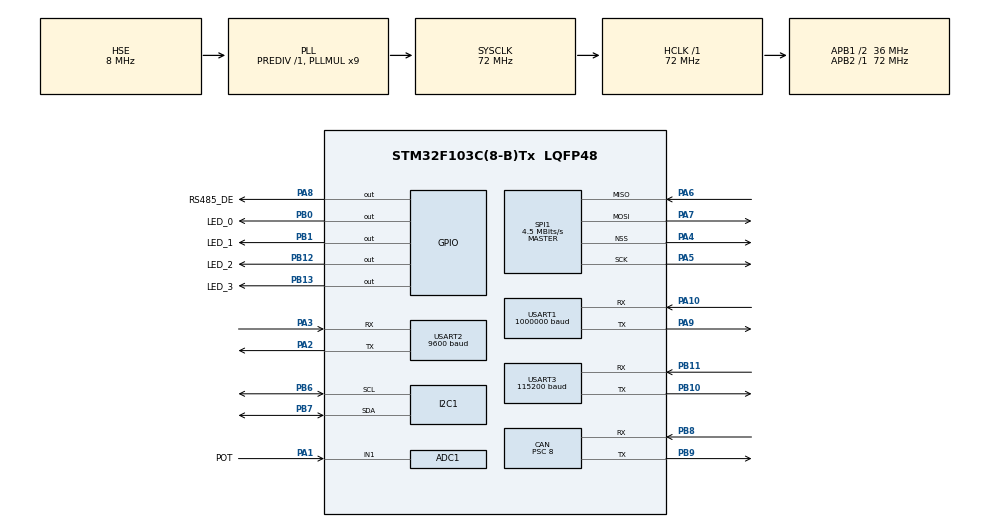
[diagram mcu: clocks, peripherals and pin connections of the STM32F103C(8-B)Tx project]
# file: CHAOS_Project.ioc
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ADC1.Channel-7\#ChannelInjectedConversion=ADC_CHANNEL_1
ADC1.Channel-8\#ChannelInjectedConversion=ADC_CHANNEL_1
ADC1.ContinuousConvMode=ENABLE
ADC1.EnableInjectedConversion=ENABLE
ADC1.EnableRegularConversion=DISABLE
ADC1.InjNumberOfConversion=2
ADC1.InjectedOffset-7\#ChannelInjectedConversion=0
ADC1.InjectedOffset-8\#ChannelInjectedConversion=0
ADC1.InjectedRank-7\#ChannelInjectedConversion=1
ADC1.InjectedRank-8\#ChannelInjectedConversion=2
ADC1.SamplingTime-7\#ChannelInjectedConversion=ADC_SAMPLETIME_1CYCLE_5
ADC1.SamplingTime-8\#ChannelInjectedConversion=ADC_SAMPLETIME_1CYCLE_5
ADC1.master=1
CAN.AWUM=ENABLE
CAN.BS1=CAN_BS1_3TQ
CAN.BS2=CAN_BS2_5TQ
CAN.CalculateBaudRate=500000
CAN.CalculateTimeBit=2000
CAN.CalculateTimeQuantum=222.22222222222223
CAN.NART=ENABLE
CAN.Prescaler=8
Mcu.Family=STM32F1
Mcu.Name=STM32F103C(8-B)Tx
Mcu.Package=LQFP48
NVIC.PriorityGroup=NVIC_PRIORITYGROUP_4
NVIC.TIM2_IRQn=true\:0\:0\:false\:false\:true\:true\:true\:true
NVIC.USB_LP_CAN1_RX0_IRQn=true\:0\:0\:false\:false\:true\:false\:true\:true
PA1.GPIO_Label=POT
PA1.Signal=ADCx_IN1
PA10.Mode=Asynchronous
PA10.Signal=USART1_RX
PA13.Mode=Serial_Wire
PA13.Signal=SYS_JTMS-SWDIO
PA14.Mode=Serial_Wire
PA14.Signal=SYS_JTCK-SWCLK
PA2.Mode=LIN
PA2.Signal=USART2_TX
PA3.Mode=LIN
PA3.Signal=USART2_RX
PA4.Mode=NSS_Signal_Hard_Output
PA4.Signal=SPI1_NSS
PA5.Mode=Full_Duplex_Master
PA5.Signal=SPI1_SCK
PA6.Mode=Full_Duplex_Master
PA6.Signal=SPI1_MISO
PA7.Mode=Full_Duplex_Master
PA7.Signal=SPI1_MOSI
PA8.GPIO_Label=RS485_DE
PA8.Signal=GPIO_Output
PA9.Mode=Asynchronous
PA9.Signal=USART1_TX
PB0.GPIO_Label=LED_0
PB0.Signal=GPIO_Output
PB1.GPIO_Label=LED_1
PB1.Signal=GPIO_Output
PB10.Mode=Asynchronous
PB10.Signal=USART3_TX
PB11.Mode=Asynchronous
PB11.Signal=USART3_RX
PB12.GPIO_Label=LED_2
PB12.Signal=GPIO_Output
PB13.GPIO_Label=LED_3
PB13.Signal=GPIO_Output
PB6.Mode=I2C
PB6.Signal=I2C1_SCL
PB7.Mode=I2C
PB7.Signal=I2C1_SDA
PB8.Mode=CAN_Activate
PB8.Signal=CAN_RX
PB9.Mode=CAN_Activate
PB9.Signal=CAN_TX
PD0-OSC_IN.Mode=HSE-External-Oscillator
PD0-OSC_IN.Signal=RCC_OSC_IN
PD1-OSC_OUT.Mode=HSE-External-Oscillator
PD1-OSC_OUT.Signal=RCC_OSC_OUT
ProjectManager.HeapSize=0x200
ProjectManager.StackSize=0x400
ProjectManager.TargetToolchain=STM32CubeIDE
RCC.ADCPresc=RCC_ADCPCLK2_DIV6
RCC.AHBFreq_Value=72000000
RCC.APB1CLKDivider=RCC_HCLK_DIV2
RCC.APB1Freq_Value=36000000
RCC.APB1TimFreq_Value=72000000
RCC.APB2Freq_Value=72000000
RCC.APB2TimFreq_Value=72000000
RCC.HCLKFreq_Value=72000000
RCC.PLLMUL=RCC_PLL_MUL9
RCC.PLLSourceVirtual=RCC_PLLSOURCE_HSE
RCC.RTCClockSelection=RCC_RTCCLKSOURCE_LSE
RCC.SYSCLKFreq_VALUE=72000000
RCC.SYSCLKSource=RCC_SYSCLKSOURCE_PLLCLK
RCC.USBFreq_Value=48000000
RCC.USBPrescaler=RCC_USBCLKSOURCE_PLL_DIV1_5
SH.ADCx_IN1.0=ADC1_IN1,IN1
SPI1.BaudRatePrescaler=SPI_BAUDRATEPRESCALER_16
SPI1.CalculateBaudRate=4.5 MBits/s
SPI1.Direction=SPI_DIRECTION_2LINES
SPI1.Mode=SPI_MODE_MASTER
SPI1.VirtualNSS=VM_NSSHARD
SPI1.VirtualType=VM_MASTER
TIM2.Period=9
TIM2.Prescaler=7200
USART1.BaudRate=1000000
USART1.VirtualMode=VM_ASYNC
USART2.BaudRate=9600
USART2.VirtualMode=VM_ASYNC
USART3.BaudRate=115200
USART3.VirtualMode=VM_ASYNC
VP_TIM2_VS_ClockSourceINT.Mode=Internal
board=custom

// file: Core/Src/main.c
/* USER CODE BEGIN Header */
/**
  ******************************************************************************
  * @file           : main.c
  * @brief          : Main program body
  ******************************************************************************
  * @attention
  *
  * Copyright (c) 2025 STMicroelectronics.
  * All rights reserved.
  *
  * This software is licensed under terms that can be found in the LICENSE file
  * in the root directory of this software component.
  * If no LICENSE file comes with this software, it is provided AS-IS.
  *
  ******************************************************************************
  */
/* USER CODE END Header */
#include "main.h"

/* USER CODE BEGIN Includes */
#include "os.h"
#include "strings.h"
#include "ssd1306.h"
#include <sys/unistd.h> // STDOUT_FILENO
#include <errno.h>
/* USER CODE END Includes */

/* USER CODE BEGIN PD */
#define UART_PRINTF
/* USER CODE END PD */

ADC_HandleTypeDef hadc1;

CAN_HandleTypeDef hcan;

I2C_HandleTypeDef hi2c1;

SPI_HandleTypeDef hspi1;

TIM_HandleTypeDef htim2;

UART_HandleTypeDef huart1;
UART_HandleTypeDef huart2;
UART_HandleTypeDef huart3;

/* USER CODE BEGIN PV */
ssd1306_t oled;
/* USER CODE END PV */

void SystemClock_Config(void);
static void MX_GPIO_Init(void);
static void MX_TIM2_Init(void);
static void MX_CAN_Init(void);
static void MX_USART1_UART_Init(void);
static void MX_USART3_UART_Init(void);
static void MX_ADC1_Init(void);
static void MX_I2C1_Init(void);
static void MX_SPI1_Init(void);
static void MX_USART2_UART_Init(void);

/* USER CODE BEGIN 0 */

/* OS tick timer interrupt */
void HAL_TIM_PeriodElapsedCallback(TIM_HandleTypeDef *htim)
{
  if(htim->Instance == TIM2)
  {
    /* OS tick service */
    Os_Tick();
  }
}

#ifdef USB_PRINTF
/* Needed to redirect printf */
int _write(int file, char *ptr, int len)
{
	/* Transmit over USB CDC */
    CDC_Transmit_FS((uint8_t*)ptr, len);
    return len;
}
#endif

#ifdef UART_PRINTF
int _write(int file, char *ptr, int len)
{
  if (file == STDOUT_FILENO || file == STDERR_FILENO) {
    HAL_UART_Transmit(&huart1, (uint8_t*)ptr, (uint16_t)len, 100);
    return len;
  }
  errno = EBADF;
  return -1;
}
#endif

/* USER CODE END 0 */

int main(void)
{

  /* MCU Configuration--------------------------------------------------------*/

  /* Reset of all peripherals, Initializes the Flash interface and the Systick. */
  HAL_Init();

  /* Configure the system clock */
  SystemClock_Config();

  /* Initialize all configured peripherals */
  MX_GPIO_Init();
  MX_TIM2_Init();
  MX_CAN_Init();
  MX_USART1_UART_Init();
  MX_USART3_UART_Init();
  MX_ADC1_Init();
  MX_I2C1_Init();
  MX_SPI1_Init();
  MX_USART2_UART_Init();
  /* USER CODE BEGIN 2 */

  /* OLED */
  ssd1306_init(&oled, &hi2c1);
  ssd1306_clear(&oled);
  ssd1306_set_cursor(&oled, 0, 0);
  ssd1306_write_string(&oled, "STARTING CHAOS", 1);
  ssd1306_set_cursor(&oled, 0, 10);
  ssd1306_write_string(&oled, "RTOS v1.0", 1);
  ssd1306_set_cursor(&oled, 0, 20);
  ssd1306_write_string(&oled, "HELLO STM32F1!", 1);
  ssd1306_update(&oled);

  /* Start timer */
  HAL_TIM_Base_Start_IT(&htim2);

  CAN_FilterTypeDef filter;

  filter.FilterBank = 0;
  filter.FilterMode = CAN_FILTERMODE_IDMASK;
  filter.FilterScale = CAN_FILTERSCALE_32BIT;

  /* Accetta tutto: ID=0, MASK=0 */
  filter.FilterIdHigh = 0x0000;
  filter.FilterIdLow  = 0x0000;
  filter.FilterMaskIdHigh = 0x0000;
  filter.FilterMaskIdLow  = 0x0000;

  filter.FilterFIFOAssignment = CAN_FILTER_FIFO0;
  filter.FilterActivation = ENABLE;

  HAL_CAN_ConfigFilter(&hcan, &filter);

  /* Start CAN */
  HAL_CAN_Start(&hcan);

  /* Start OS */
  Os_Start();

  /* USER CODE END 2 */

  /* Infinite loop */
  while (1)
  {

  }
}

void SystemClock_Config(void)
{
  RCC_OscInitTypeDef RCC_OscInitStruct = {0};
  RCC_ClkInitTypeDef RCC_ClkInitStruct = {0};
  RCC_PeriphCLKInitTypeDef PeriphClkInit = {0};

  /** Initializes the RCC Oscillators according to the specified parameters
  * in the RCC_OscInitTypeDef structure.
  */
  RCC_OscInitStruct.OscillatorType = RCC_OSCILLATORTYPE_HSE;
  RCC_OscInitStruct.HSEState = RCC_HSE_ON;
  RCC_OscInitStruct.HSEPredivValue = RCC_HSE_PREDIV_DIV1;
  RCC_OscInitStruct.HSIState = RCC_HSI_ON;
  RCC_OscInitStruct.PLL.PLLState = RCC_PLL_ON;
  RCC_OscInitStruct.PLL.PLLSource = RCC_PLLSOURCE_HSE;
  RCC_OscInitStruct.PLL.PLLMUL = RCC_PLL_MUL9;
  if (HAL_RCC_OscConfig(&RCC_OscInitStruct) != HAL_OK)
  {
    Error_Handler();
  }

  /** Initializes the CPU, AHB and APB buses clocks
  */
  RCC_ClkInitStruct.ClockType = RCC_CLOCKTYPE_HCLK|RCC_CLOCKTYPE_SYSCLK
                              |RCC_CLOCKTYPE_PCLK1|RCC_CLOCKTYPE_PCLK2;
  RCC_ClkInitStruct.SYSCLKSource = RCC_SYSCLKSOURCE_PLLCLK;
  RCC_ClkInitStruct.AHBCLKDivider = RCC_SYSCLK_DIV1;
  RCC_ClkInitStruct.APB1CLKDivider = RCC_HCLK_DIV2;
  RCC_ClkInitStruct.APB2CLKDivider = RCC_HCLK_DIV1;

  if (HAL_RCC_ClockConfig(&RCC_ClkInitStruct, FLASH_LATENCY_2) != HAL_OK)
  {
    Error_Handler();
  }
  PeriphClkInit.PeriphClockSelection = RCC_PERIPHCLK_ADC;
  PeriphClkInit.AdcClockSelection = RCC_ADCPCLK2_DIV6;
  if (HAL_RCCEx_PeriphCLKConfig(&PeriphClkInit) != HAL_OK)
  {
    Error_Handler();
  }
}

static void MX_ADC1_Init(void)
{

  ADC_InjectionConfTypeDef sConfigInjected = {0};

  /** Common config
  */
  hadc1.Instance = ADC1;
  hadc1.Init.ScanConvMode = ADC_SCAN_ENABLE;
  hadc1.Init.ContinuousConvMode = ENABLE;
  hadc1.Init.DiscontinuousConvMode = DISABLE;
  hadc1.Init.ExternalTrigConv = ADC_SOFTWARE_START;
  hadc1.Init.DataAlign = ADC_DATAALIGN_RIGHT;
  hadc1.Init.NbrOfConversion = 1;
  if (HAL_ADC_Init(&hadc1) != HAL_OK)
  {
    Error_Handler();
  }

  /** Configure Injected Channel
  */
  sConfigInjected.InjectedChannel = ADC_CHANNEL_1;
  sConfigInjected.InjectedRank = ADC_INJECTED_RANK_1;
  sConfigInjected.InjectedNbrOfConversion = 2;
  sConfigInjected.InjectedSamplingTime = ADC_SAMPLETIME_1CYCLE_5;
  sConfigInjected.ExternalTrigInjecConv = ADC_INJECTED_SOFTWARE_START;
  sConfigInjected.AutoInjectedConv = DISABLE;
  sConfigInjected.InjectedDiscontinuousConvMode = DISABLE;
  sConfigInjected.InjectedOffset = 0;
  if (HAL_ADCEx_InjectedConfigChannel(&hadc1, &sConfigInjected) != HAL_OK)
  {
    Error_Handler();
  }

  /** Configure Injected Channel
  */
  sConfigInjected.InjectedRank = ADC_INJECTED_RANK_2;
  if (HAL_ADCEx_InjectedConfigChannel(&hadc1, &sConfigInjected) != HAL_OK)
  {
    Error_Handler();
  }

}

static void MX_CAN_Init(void)
{

  hcan.Instance = CAN1;
  hcan.Init.Prescaler = 8;
  hcan.Init.Mode = CAN_MODE_NORMAL;
  hcan.Init.SyncJumpWidth = CAN_SJW_1TQ;
  hcan.Init.TimeSeg1 = CAN_BS1_3TQ;
  hcan.Init.TimeSeg2 = CAN_BS2_5TQ;
  hcan.Init.TimeTriggeredMode = DISABLE;
  hcan.Init.AutoBusOff = DISABLE;
  hcan.Init.AutoWakeUp = ENABLE;
  hcan.Init.AutoRetransmission = ENABLE;
  hcan.Init.ReceiveFifoLocked = DISABLE;
  hcan.Init.TransmitFifoPriority = DISABLE;
  if (HAL_CAN_Init(&hcan) != HAL_OK)
  {
    Error_Handler();
  }

}

static void MX_I2C1_Init(void)
{

  hi2c1.Instance = I2C1;
  hi2c1.Init.ClockSpeed = 100000;
  hi2c1.Init.DutyCycle = I2C_DUTYCYCLE_2;
  hi2c1.Init.OwnAddress1 = 0;
  hi2c1.Init.AddressingMode = I2C_ADDRESSINGMODE_7BIT;
  hi2c1.Init.DualAddressMode = I2C_DUALADDRESS_DISABLE;
  hi2c1.Init.OwnAddress2 = 0;
  hi2c1.Init.GeneralCallMode = I2C_GENERALCALL_DISABLE;
  hi2c1.Init.NoStretchMode = I2C_NOSTRETCH_DISABLE;
  if (HAL_I2C_Init(&hi2c1) != HAL_OK)
  {
    Error_Handler();
  }

}

static void MX_SPI1_Init(void)
{

  /* SPI1 parameter configuration*/
  hspi1.Instance = SPI1;
  hspi1.Init.Mode = SPI_MODE_MASTER;
  hspi1.Init.Direction = SPI_DIRECTION_2LINES;
  hspi1.Init.DataSize = SPI_DATASIZE_8BIT;
  hspi1.Init.CLKPolarity = SPI_POLARITY_LOW;
  hspi1.Init.CLKPhase = SPI_PHASE_1EDGE;
  hspi1.Init.NSS = SPI_NSS_HARD_OUTPUT;
  hspi1.Init.BaudRatePrescaler = SPI_BAUDRATEPRESCALER_16;
  hspi1.Init.FirstBit = SPI_FIRSTBIT_MSB;
  hspi1.Init.TIMode = SPI_TIMODE_DISABLE;
  hspi1.Init.CRCCalculation = SPI_CRCCALCULATION_DISABLE;
  hspi1.Init.CRCPolynomial = 10;
  if (HAL_SPI_Init(&hspi1) != HAL_OK)
  {
    Error_Handler();
  }

}

static void MX_TIM2_Init(void)
{

  TIM_ClockConfigTypeDef sClockSourceConfig = {0};
  TIM_MasterConfigTypeDef sMasterConfig = {0};

  htim2.Instance = TIM2;
  htim2.Init.Prescaler = 7200;
  htim2.Init.CounterMode = TIM_COUNTERMODE_UP;
  htim2.Init.Period = 9;
  htim2.Init.ClockDivision = TIM_CLOCKDIVISION_DIV1;
  htim2.Init.AutoReloadPreload = TIM_AUTORELOAD_PRELOAD_DISABLE;
  if (HAL_TIM_Base_Init(&htim2) != HAL_OK)
  {
    Error_Handler();
  }
  sClockSourceConfig.ClockSource = TIM_CLOCKSOURCE_INTERNAL;
  if (HAL_TIM_ConfigClockSource(&htim2, &sClockSourceConfig) != HAL_OK)
  {
    Error_Handler();
  }
  sMasterConfig.MasterOutputTrigger = TIM_TRGO_RESET;
  sMasterConfig.MasterSlaveMode = TIM_MASTERSLAVEMODE_DISABLE;
  if (HAL_TIMEx_MasterConfigSynchronization(&htim2, &sMasterConfig) != HAL_OK)
  {
    Error_Handler();
  }

}

static void MX_USART1_UART_Init(void)
{

  huart1.Instance = USART1;
  huart1.Init.BaudRate = 1000000;
  huart1.Init.WordLength = UART_WORDLENGTH_8B;
  huart1.Init.StopBits = UART_STOPBITS_1;
  huart1.Init.Parity = UART_PARITY_NONE;
  huart1.Init.Mode = UART_MODE_TX_RX;
  huart1.Init.HwFlowCtl = UART_HWCONTROL_NONE;
  huart1.Init.OverSampling = UART_OVERSAMPLING_16;
  if (HAL_UART_Init(&huart1) != HAL_OK)
  {
    Error_Handler();
  }

}

static void MX_USART2_UART_Init(void)
{

  huart2.Instance = USART2;
  huart2.Init.BaudRate = 9600;
  huart2.Init.WordLength = UART_WORDLENGTH_8B;
  huart2.Init.StopBits = UART_STOPBITS_1;
  huart2.Init.Parity = UART_PARITY_NONE;
  huart2.Init.Mode = UART_MODE_TX_RX;
  huart2.Init.HwFlowCtl = UART_HWCONTROL_NONE;
  if (HAL_LIN_Init(&huart2, UART_LINBREAKDETECTLENGTH_10B) != HAL_OK)
  {
    Error_Handler();
  }

}

static void MX_USART3_UART_Init(void)
{

  huart3.Instance = USART3;
  huart3.Init.BaudRate = 115200;
  huart3.Init.WordLength = UART_WORDLENGTH_8B;
  huart3.Init.StopBits = UART_STOPBITS_1;
  huart3.Init.Parity = UART_PARITY_NONE;
  huart3.Init.Mode = UART_MODE_TX_RX;
  huart3.Init.HwFlowCtl = UART_HWCONTROL_NONE;
  huart3.Init.OverSampling = UART_OVERSAMPLING_16;
  if (HAL_UART_Init(&huart3) != HAL_OK)
  {
    Error_Handler();
  }

}

static void MX_GPIO_Init(void)
{
  GPIO_InitTypeDef GPIO_InitStruct = {0};

  /* GPIO Ports Clock Enable */
  __HAL_RCC_GPIOD_CLK_ENABLE();
  __HAL_RCC_GPIOA_CLK_ENABLE();
  __HAL_RCC_GPIOB_CLK_ENABLE();

  /*Configure GPIO pin Output Level */
  HAL_GPIO_WritePin(GPIOB, LED_0_Pin|LED_1_Pin|LED_2_Pin|LED_3_Pin, GPIO_PIN_RESET);

  /*Configure GPIO pin Output Level */
  HAL_GPIO_WritePin(GPIOA, RS485_DE_Pin|BUZZ_Pin, GPIO_PIN_RESET);

  /*Configure GPIO pins : LED_0_Pin LED_1_Pin LED_2_Pin LED_3_Pin */
  GPIO_InitStruct.Pin = LED_0_Pin|LED_1_Pin|LED_2_Pin|LED_3_Pin;
  GPIO_InitStruct.Mode = GPIO_MODE_OUTPUT_PP;
  GPIO_InitStruct.Pull = GPIO_NOPULL;
  GPIO_InitStruct.Speed = GPIO_SPEED_FREQ_LOW;
  HAL_GPIO_Init(GPIOB, &GPIO_InitStruct);

  /*Configure GPIO pin : RS485_DE_Pin */
  GPIO_InitStruct.Pin = RS485_DE_Pin;
  GPIO_InitStruct.Mode = GPIO_MODE_OUTPUT_PP;
  GPIO_InitStruct.Pull = GPIO_NOPULL;
  GPIO_InitStruct.Speed = GPIO_SPEED_FREQ_LOW;
  HAL_GPIO_Init(RS485_DE_GPIO_Port, &GPIO_InitStruct);

  /*Configure GPIO pin : BUZZ_Pin */
  GPIO_InitStruct.Pin = BUZZ_Pin;
  GPIO_InitStruct.Mode = GPIO_MODE_OUTPUT_PP;
  GPIO_InitStruct.Pull = GPIO_PULLDOWN;
  GPIO_InitStruct.Speed = GPIO_SPEED_FREQ_LOW;
  HAL_GPIO_Init(BUZZ_GPIO_Port, &GPIO_InitStruct);

}

void Error_Handler(void)
{
  __disable_irq();
  while (1)
  {
  }
}
